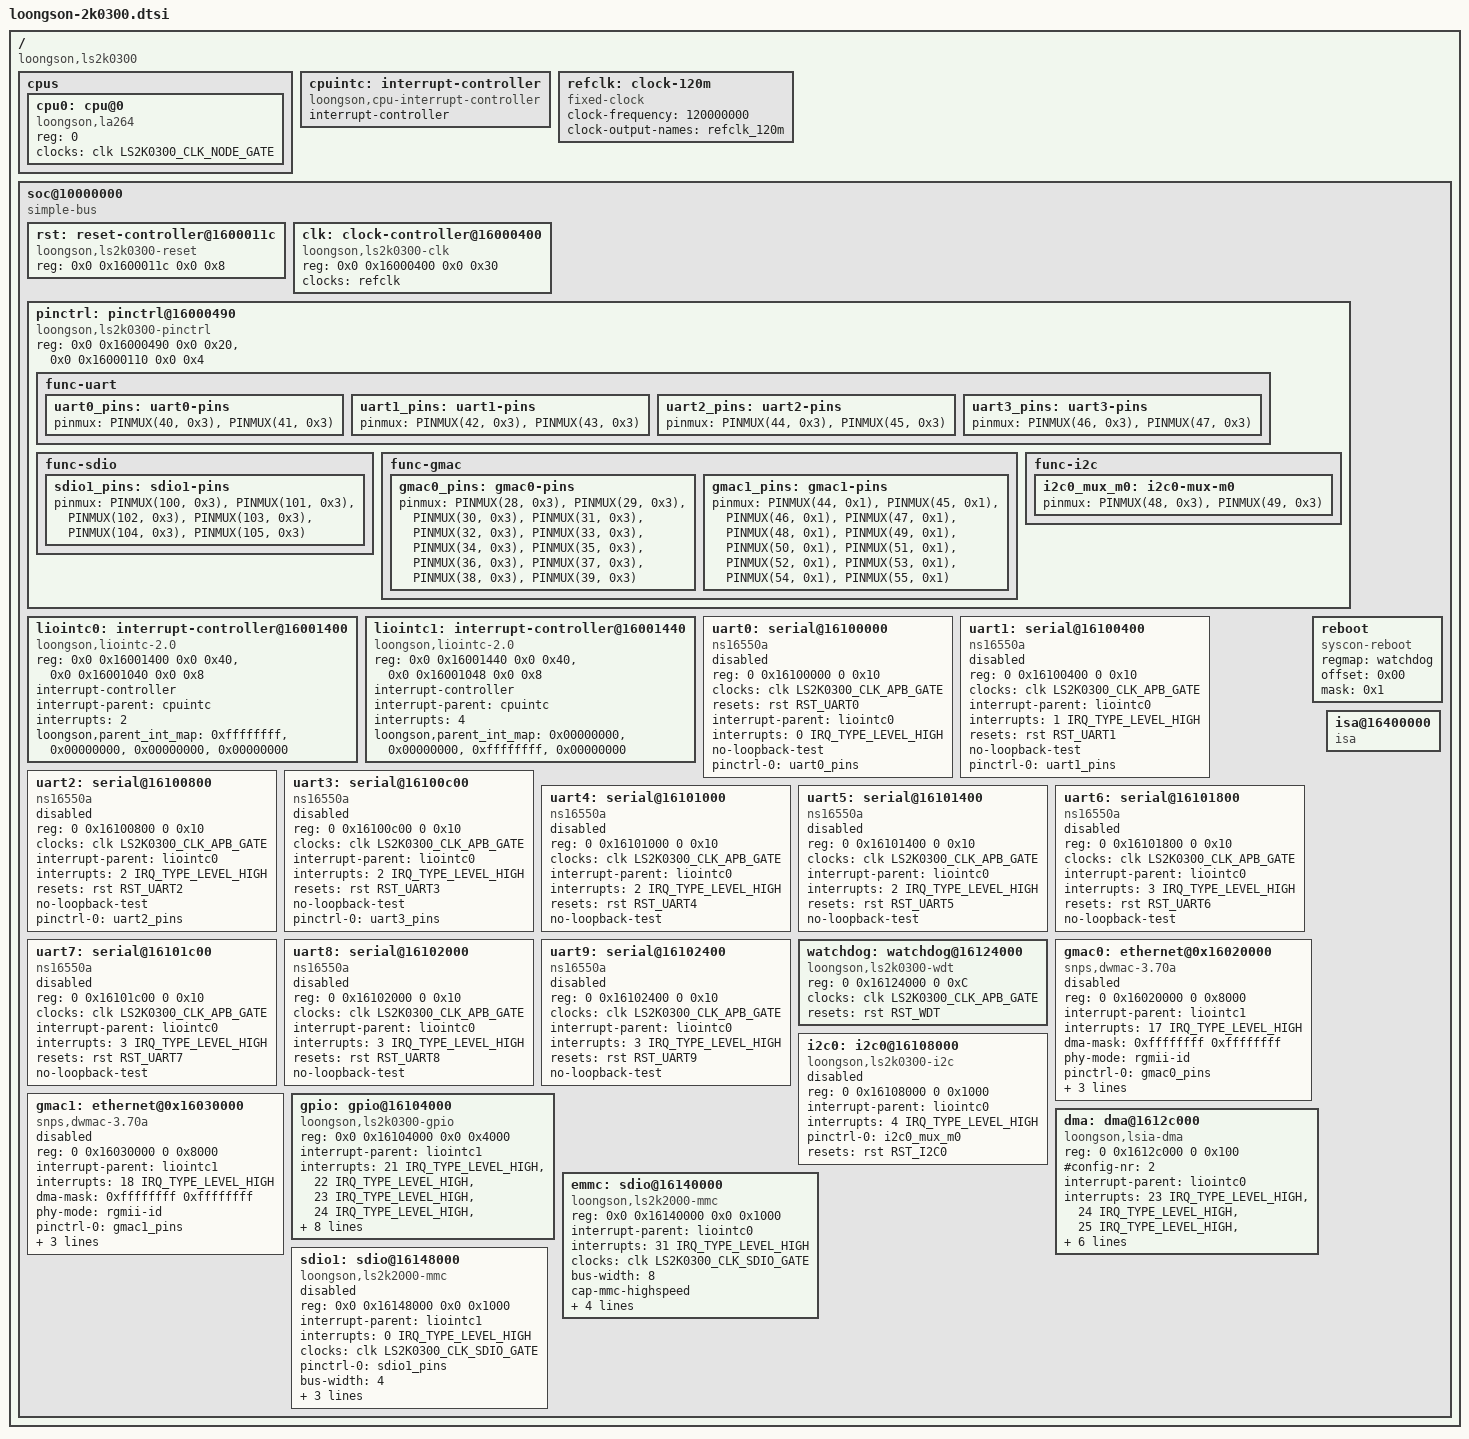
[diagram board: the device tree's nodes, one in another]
// SPDX-License-Identifier: GPL-2.0
/*
 * Copyright (C) 2025 Loongson Technology Corporation Limited
 * Copyright (C) 2025 Yao Zi <ziyao@disroot.org>
 */

/dts-v1/;

#include <dt-bindings/clock/loongson,ls2k-clk.h>
#include <dt-bindings/reset/loongson,ls2k0300-reset.h>
#include <dt-bindings/interrupt-controller/irq.h>
#include <dt-bindings/gpio/gpio.h>
#include <dt-bindings/clock/loongson,ls1x-clk.h>

#define PINMUX(pin, func)	(((pin) << 8) | func)

/ {
	compatible = "loongson,ls2k0300";
	#address-cells = <2>;
	#size-cells = <2>;

	cpus {
		#address-cells = <1>;
		#size-cells = <0>;

		cpu0: cpu@0 {
			compatible = "loongson,la264";
			reg = <0>;
			device_type = "cpu";
			clocks = <&clk LS2K0300_CLK_NODE_GATE>;
		};

	};

	cpuintc: interrupt-controller {
		compatible = "loongson,cpu-interrupt-controller";
		interrupt-controller;
		#interrupt-cells = <1>;
	};

	refclk: clock-120m {
		compatible = "fixed-clock";
		clock-frequency = <120000000>;
		clock-output-names = "refclk_120m";
		#clock-cells = <0>;
	};

	soc@10000000 {
		compatible = "simple-bus";
		#address-cells = <2>;
		#size-cells = <2>;
		ranges = <0x00 0x10000000 0x00 0x10000000 0x0 0x10000000>,
			 <0x00 0x02000000 0x00 0x02000000 0x0 0x04000000>,
			 <0x00 0x40000000 0x00 0x40000000 0x0 0x40000000>;

		rst: reset-controller@1600011c {
			compatible = "loongson,ls2k0300-reset";
			reg = <0x0 0x1600011c 0x0 0x8>;
			#reset-cells = <1>;
		};

		clk: clock-controller@16000400 {
			compatible = "loongson,ls2k0300-clk";
			reg = <0x0 0x16000400 0x0 0x30>;
			clocks = <&refclk>;
			#clock-cells = <1>;
		};

		pinctrl: pinctrl@16000490 {
			compatible = "loongson,ls2k0300-pinctrl";
			reg = <0x0 0x16000490 0x0 0x20>,
			      <0x0 0x16000110 0x0 0x4>;
			reg-names = "mux", "drive";

			func-uart {
				uart0_pins: uart0-pins {
					pinmux = <PINMUX(40, 0x3)>,
						 <PINMUX(41, 0x3)>;
				};

				uart1_pins: uart1-pins {
					pinmux = <PINMUX(42, 0x3)>,
						 <PINMUX(43, 0x3)>;
				};

				uart2_pins: uart2-pins {
					pinmux = <PINMUX(44, 0x3)>,
						 <PINMUX(45, 0x3)>;
				};

				uart3_pins: uart3-pins {
					pinmux = <PINMUX(46, 0x3)>,
						 <PINMUX(47, 0x3)>;
				};
			};

			func-sdio {
				sdio1_pins: sdio1-pins {
					pinmux = <PINMUX(100, 0x3)>,
						 <PINMUX(101, 0x3)>,
						 <PINMUX(102, 0x3)>,
						 <PINMUX(103, 0x3)>,
						 <PINMUX(104, 0x3)>,
						 <PINMUX(105, 0x3)>;
				};
			};

			func-gmac {
				gmac0_pins: gmac0-pins {
					pinmux = <PINMUX(28, 0x3)>,
						 <PINMUX(29, 0x3)>,
						 <PINMUX(30, 0x3)>,
						 <PINMUX(31, 0x3)>,
						 <PINMUX(32, 0x3)>,
						 <PINMUX(33, 0x3)>,
						 <PINMUX(34, 0x3)>,
						 <PINMUX(35, 0x3)>,
						 <PINMUX(36, 0x3)>,
						 <PINMUX(37, 0x3)>,
						 <PINMUX(38, 0x3)>,
						 <PINMUX(39, 0x3)>;
				};

				gmac1_pins: gmac1-pins {
					pinmux = <PINMUX(44, 0x1)>,
						 <PINMUX(45, 0x1)>,
						 <PINMUX(46, 0x1)>,
						 <PINMUX(47, 0x1)>,
						 <PINMUX(48, 0x1)>,
						 <PINMUX(49, 0x1)>,
						 <PINMUX(50, 0x1)>,
						 <PINMUX(51, 0x1)>,
						 <PINMUX(52, 0x1)>,
						 <PINMUX(53, 0x1)>,
						 <PINMUX(54, 0x1)>,
						 <PINMUX(55, 0x1)>;
				};
			};

			func-i2c {
				i2c0_mux_m0: i2c0-mux-m0 {
					pinmux = <PINMUX(48, 0x3)>,
						 <PINMUX(49, 0x3)>;
				};
			};
		};

		liointc0: interrupt-controller@16001400 {
			compatible = "loongson,liointc-2.0";
			reg = <0x0 0x16001400 0x0 0x40>,
			      <0x0 0x16001040 0x0 0x8>;
			reg-names = "main", "isr0";

			interrupt-controller;
			#interrupt-cells = <2>;

			interrupt-parent = <&cpuintc>;
			interrupts = <2>;
			interrupt-names = "int0";

			loongson,parent_int_map = <0xffffffff>, /* int0 */
						  <0x00000000>, /* int1 */
						  <0x00000000>, /* int2 */
						  <0x00000000>; /* int3 */
		};

		liointc1: interrupt-controller@16001440 {
			compatible = "loongson,liointc-2.0";
			reg = <0x0 0x16001440 0x0 0x40>,
			      <0x0 0x16001048 0x0 0x8>;
			reg-names = "main", "isr0";

			interrupt-controller;
			#interrupt-cells = <2>;

			interrupt-parent = <&cpuintc>;
			interrupts = <4>;
			interrupt-names = "int2";

			loongson,parent_int_map = <0x00000000>, /* int0 */
						  <0x00000000>, /* int1 */
						  <0xffffffff>, /* int2 */
						  <0x00000000>; /* int3 */
		};

		uart0: serial@16100000 {
			compatible = "ns16550a";
			reg = <0 0x16100000 0 0x10>;
			clocks = <&clk LS2K0300_CLK_APB_GATE>;
			resets = <&rst RST_UART0>;
			interrupt-parent = <&liointc0>;
			interrupts = <0 IRQ_TYPE_LEVEL_HIGH>;
			no-loopback-test;
			pinctrl-names = "default";
			pinctrl-0 = <&uart0_pins>;
			status = "disabled";
		};

		uart1: serial@16100400 {
			compatible = "ns16550a";
			reg = <0 0x16100400 0 0x10>;
			clocks = <&clk LS2K0300_CLK_APB_GATE>;
			interrupt-parent = <&liointc0>;
			interrupts = <1 IRQ_TYPE_LEVEL_HIGH>;
			resets = <&rst RST_UART1>;
			no-loopback-test;
			pinctrl-names = "default";
			pinctrl-0 = <&uart1_pins>;
			status = "disabled";
		};

		uart2: serial@16100800 {
			compatible = "ns16550a";
			reg = <0 0x16100800 0 0x10>;
			clocks = <&clk LS2K0300_CLK_APB_GATE>;
			interrupt-parent = <&liointc0>;
			interrupts = <2 IRQ_TYPE_LEVEL_HIGH>;
			resets = <&rst RST_UART2>;
			no-loopback-test;
			pinctrl-names = "default";
			pinctrl-0 = <&uart2_pins>;
			status = "disabled";
		};

		uart3: serial@16100c00 {
			compatible = "ns16550a";
			reg = <0 0x16100c00 0 0x10>;
			clocks = <&clk LS2K0300_CLK_APB_GATE>;
			interrupt-parent = <&liointc0>;
			interrupts = <2 IRQ_TYPE_LEVEL_HIGH>;
			resets = <&rst RST_UART3>;
			no-loopback-test;
			pinctrl-names = "default";
			pinctrl-0 = <&uart3_pins>;
			status = "disabled";
		};

		uart4: serial@16101000 {
			compatible = "ns16550a";
			reg = <0 0x16101000 0 0x10>;
			clocks = <&clk LS2K0300_CLK_APB_GATE>;
			interrupt-parent = <&liointc0>;
			interrupts = <2 IRQ_TYPE_LEVEL_HIGH>;
			resets = <&rst RST_UART4>;
			no-loopback-test;
			status = "disabled";
		};

		uart5: serial@16101400 {
			compatible = "ns16550a";
			reg = <0 0x16101400 0 0x10>;
			clocks = <&clk LS2K0300_CLK_APB_GATE>;
			interrupt-parent = <&liointc0>;
			interrupts = <2 IRQ_TYPE_LEVEL_HIGH>;
			resets = <&rst RST_UART5>;
			no-loopback-test;
			status = "disabled";
		};

		uart6: serial@16101800 {
			compatible = "ns16550a";
			reg = <0 0x16101800 0 0x10>;
			clocks = <&clk LS2K0300_CLK_APB_GATE>;
			interrupt-parent = <&liointc0>;
			interrupts = <3 IRQ_TYPE_LEVEL_HIGH>;
			resets = <&rst RST_UART6>;
			no-loopback-test;
			status = "disabled";
		};

		uart7: serial@16101c00 {
			compatible = "ns16550a";
			reg = <0 0x16101c00 0 0x10>;
			clocks = <&clk LS2K0300_CLK_APB_GATE>;
			interrupt-parent = <&liointc0>;
			interrupts = <3 IRQ_TYPE_LEVEL_HIGH>;
			resets = <&rst RST_UART7>;
			no-loopback-test;
			status = "disabled";
		};

		uart8: serial@16102000 {
			compatible = "ns16550a";
			reg = <0 0x16102000 0 0x10>;
			clocks = <&clk LS2K0300_CLK_APB_GATE>;
			interrupt-parent = <&liointc0>;
			interrupts = <3 IRQ_TYPE_LEVEL_HIGH>;
			resets = <&rst RST_UART8>;
			no-loopback-test;
			status = "disabled";
		};

		uart9: serial@16102400 {
			compatible = "ns16550a";
			reg = <0 0x16102400 0 0x10>;
			clocks = <&clk LS2K0300_CLK_APB_GATE>;
			interrupt-parent = <&liointc0>;
			interrupts = <3 IRQ_TYPE_LEVEL_HIGH>;
			resets = <&rst RST_UART9>;
			no-loopback-test;
			status = "disabled";
		};

		watchdog: watchdog@16124000 {
			compatible = "loongson,ls2k0300-wdt", "syscon";
			reg = <0 0x16124000 0 0xC>;
			clocks = <&clk LS2K0300_CLK_APB_GATE>;
			resets = <&rst RST_WDT>;
			status = "okay";
		};

		reboot {
			compatible ="syscon-reboot";
			regmap = <&watchdog>;
			offset = <0x00>;
			mask = <0x1>;
		};

		gmac0: ethernet@0x16020000 {
			compatible = "snps,dwmac-3.70a";
			reg = <0 0x16020000 0 0x8000>;
			interrupt-parent = <&liointc1>;
			interrupts = <17 IRQ_TYPE_LEVEL_HIGH>; // 49 - 32 = 17
			interrupt-names = "macirq";
			dma-mask = <0xffffffff 0xffffffff>;
			phy-mode = "rgmii-id";
			pinctrl-0 = <&gmac0_pins>;
			pinctrl-names = "default";
			snps,pbl = <32>;
			resets = <&rst RST_GMAC0>;
        	clocks = <&clk LS2K0300_CLK_GMAC_GATE>;
        	clock-names = "stmmaceth";
			status = "disabled";
		};

		gmac1: ethernet@0x16030000 {
			compatible = "snps,dwmac-3.70a";
			reg = <0 0x16030000 0 0x8000>;
			interrupt-parent = <&liointc1>;
			interrupts = <18 IRQ_TYPE_LEVEL_HIGH>; // 50 - 32 = 18
			interrupt-names = "macirq";
			dma-mask = <0xffffffff 0xffffffff>;
			phy-mode = "rgmii-id";
			pinctrl-0 = <&gmac1_pins>;
			pinctrl-names = "default";
			snps,pbl = <32>;
			resets = <&rst RST_GMAC1>;
        	clocks = <&clk LS2K0300_CLK_GMAC_GATE>;
        	clock-names = "stmmaceth";
			status = "disabled";
		};

		gpio: gpio@16104000 {
			compatible = "loongson,ls2k0300-gpio";
			reg = <0x0 0x16104000 0x0 0x4000>;
			interrupt-parent = <&liointc1>;
			interrupts = <21 IRQ_TYPE_LEVEL_HIGH>,
				     <22 IRQ_TYPE_LEVEL_HIGH>,
				     <23 IRQ_TYPE_LEVEL_HIGH>,
				     <24 IRQ_TYPE_LEVEL_HIGH>,
				     <25 IRQ_TYPE_LEVEL_HIGH>,
				     <26 IRQ_TYPE_LEVEL_HIGH>,
				     <27 IRQ_TYPE_LEVEL_HIGH>;
			ngpios = <106>;
			gpio-controller;
			gpio-ranges = <&pinctrl 0 0 106>;
			#gpio-cells = <2>;
			interrupt-controller;
			#interrupt-cells = <2>;
			resets = <&rst RST_GPIO>;
		};

		i2c0: i2c0@16108000 {
			compatible = "loongson,ls2k0300-i2c";
			reg = <0 0x16108000 0 0x1000>;
			interrupt-parent = <&liointc0>;
			interrupts = <4 IRQ_TYPE_LEVEL_HIGH>;
			#address-cells = <1>;
			#size-cells = <0>;

			pinctrl-0 = <&i2c0_mux_m0>;
			pinctrl-names = "default";
			resets = <&rst RST_I2C0>;
			status = "disabled";
		};

		dma: dma@1612c000{
			compatible = "loongson,lsia-dma";
			reg = <0 0x1612c000 0 0x100>;
			#config-nr = <2>;
			interrupt-parent = <&liointc0>;
			interrupts = <23 IRQ_TYPE_LEVEL_HIGH>, <24 IRQ_TYPE_LEVEL_HIGH>,
			<25 IRQ_TYPE_LEVEL_HIGH>, <26 IRQ_TYPE_LEVEL_HIGH>,
			<27 IRQ_TYPE_LEVEL_HIGH>, <28 IRQ_TYPE_LEVEL_HIGH>,
			<29 IRQ_TYPE_LEVEL_HIGH>, <30 IRQ_TYPE_LEVEL_HIGH>;
			#dma-cells = <2>;
			dma-channels = <8>;
		};

		emmc: sdio@16140000 {
			compatible = "loongson,ls2k2000-mmc";
			reg = <0x0 0x16140000 0x0 0x1000>;
			interrupt-parent = <&liointc0>;
			interrupts = <31 IRQ_TYPE_LEVEL_HIGH>;
			clocks = <&clk LS2K0300_CLK_SDIO_GATE>;
			bus-width = <8>;
			cap-mmc-highspeed;
			no-sd;
			no-sdio;
			non-removable;
			resets = <&rst RST_SDIO0>;
		};

		sdio1: sdio@16148000 {
			compatible = "loongson,ls2k2000-mmc";
			reg = <0x0 0x16148000 0x0 0x1000>;
			interrupt-parent = <&liointc1>;
			interrupts = <0 IRQ_TYPE_LEVEL_HIGH>; // 32 - 32 = 0
			clocks = <&clk LS2K0300_CLK_SDIO_GATE>;
			pinctrl-0 = <&sdio1_pins>;
			pinctrl-names = "default";
			bus-width = <4>;
			cap-sd-highspeed;
			cap-mmc-highspeed;
			resets = <&rst RST_SDIO1>;
			status = "disabled";
		};

		isa@16400000 {
			compatible = "isa";
			#address-cells = <2>;
			#size-cells = <1>;
			ranges = <1 0x0 0x0 0x16400000 0x4000>;
		};
	};
};
